# max32665 register map
Vendor: Maxim-Integrated; Series: ARMCM3; File version: 1.0
CPU: CM4 r2p1, little endian, MPU, FPU, 3 interrupt priority bits
Registers are 32-bit, read-write, reset 0x0 unless marked. A register's access mark holds for its fields unless they carry their own. Offsets are from the block's base; [hi:lo] are bit positions; {n}, {i} and the like mark numbered series; 'fields as' and 'values as' point back to an identical list.

## SPIXR — SPIXR peripheral.
Base 0x4003A000
0x00 DATA32 — Register for reading and writing the FIFO.
  [31:0] DATA — Read to pull from RX FIFO, write to put into TX FIFO.
{0x0+2i} DATA16[{i}] (i=0..1) 16-bit (alternate view of DATA32) — Register for reading and writing the FIFO.
  [15:0] DATA — Read to pull from RX FIFO, write to put into TX FIFO.
{0x0+i} DATA8[{i}] (i=0..3) 8-bit (alternate view of DATA32) — Register for reading and writing the FIFO.
  [7:0] DATA — Read to pull from RX FIFO, write to put into TX FIFO.
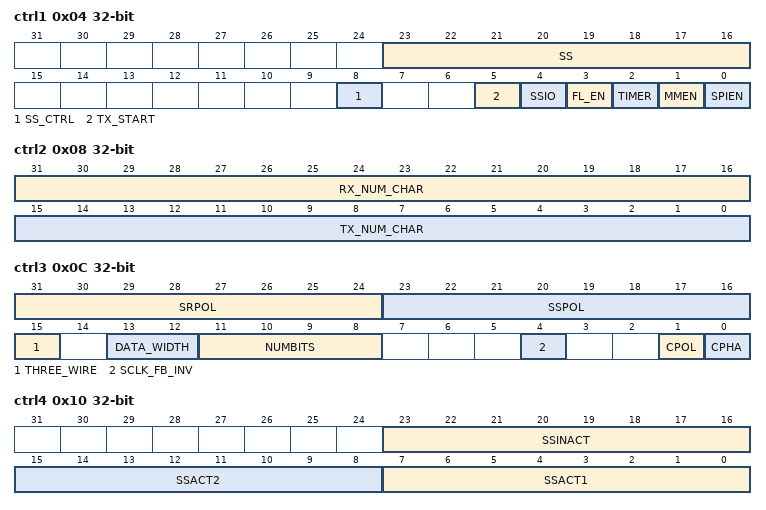
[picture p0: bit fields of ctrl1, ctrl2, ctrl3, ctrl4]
0x04 ctrl1 — Register for controlling SPI peripheral.
  [23:16] SS — Slave Select, when in Master mode selects which Slave devices are selected. More than one Slave device can be selected.
    1=SS0 is selected; 2=SS1 is selected; 4=SS2 is selected; 8=SS3 is selected; 16=SS4 is selected; 32=SS5 is selected; 64=SS6 is selected; 128=SS7 is selected
  [8] SS_CTRL — Slave Select Control.
    0=deassert (SPI de-asserts Slave Select at the end of a transaction.); 1=assert (SPI leaves Slave Select asserted at the end of a transaction.)
  [5] TX_START — Start Transmit.
    1=start (Master Initiates a transaction, this bit is self clearing when transactions are done. If a transaction completes, and the TX FIFO is empty, the Master halts, if a transaction completes, and the TX FIFO is not empty, the Master initiates another transaction.)
  [4] SSIO — Slave Select 0, IO direction, to support Multi-Master mode, Slave Select 0 can be input in Master mode. This bit has no effect in slave mode.
    0=output (Slave select 0 is output.); 1=input (Slave Select 0 is input, only valid if MMEN=1.)
  [3] FL_EN — Flow Control Mode Enable.
    0=dis (Flow Control mode is disabled.); 1=en (Flow Control Mode is enabled.)
  [2] TIMER — Timer Enable.
    0=dis (Timer is disabled.); 1=en (Timer is enabled, only valid if SPIEN=0.)
  [1] MMEN — Master Mode Enable.
    0=dis (SPI is Slave mode.); 1=en (SPI is Master mode.)
  [0] SPIEN — SPI Enable.
    0=dis (SPI is disabled.); 1=en (SPI is enabled.)
0x08 ctrl2 — Register for controlling SPI peripheral.
  [31:16] RX_NUM_CHAR — Nubmer of Characters to receive.
  [15:0] TX_NUM_CHAR — Nubmer of Characters to transmit.
0x0C ctrl3 — Register for controlling SPI peripheral.
  [31:24] SRPOL — Slave Ready Polarity, each Slave Ready can have unique polarity.
    1=SR0_high (SR0 active high.); 2=SR1_high (SR1 active high.); 4=SR2_high (SR2 active high.); 8=SR3_high (SR3 active high.); 16=SR4_high (SR4 active high.); 32=SR5_high (SR5 active high.); 64=SR6_high (SR6 active high.); 128=SR7_high (SR7 active high.)
  [23:16] SSPOL — Slave Select Polarity, each Slave Select can have unique polarity.
    1=SS0_high (SS0 active high.); 2=SS1_high (SS1 active high.); 4=SS2_high (SS2 active high.); 8=SS3_high (SS3 active high.); 16=SS4_high (SS4 active high.); 32=SS5_high (SS5 active high.); 64=SS6_high (SS6 active high.); 128=SS7_high (SS7 active high.)
  [15] THREE_WIRE — Three Wire mode. MOSI/MISO pin(s) shared. Only Mono mode suports Four-Wire.
    0=dis (Use four wire mode (Mono only).); 1=en (Use three wire mode.)
  [13:12] DATA_WIDTH — SPI Data width.
    0=Mono (1 data pin.); 1=Dual (2 data pins.); 2=Quad (4 data pins.)
  [11:8] NUMBITS — Number of Bits per character.
    0=16 bits per character
  [4] SCLK_FB_INV — Invert SCLK Feedback in Master Mode.
    0=NON_INV (SCLK is not inverted to Line Receiver.); 1=INV (SCLK is inverted to Line Receiver.)
  [1] CPOL — Clock Polarity.
  [0] CPHA — Clock Phase.
0x10 ctrl4 — Register for controlling SPI peripheral.
  [23:16] SSINACT — Slave Select Inactive delay.
    0=256 system clocks between transactions
  [15:8] SSACT2 — Slave Select Action delay 2.
    0=256 system clocks between last serial clock edge and SS inactive
  [7:0] SSACT1 — Slave Select Action delay 1.
    0=256 system clocks between SS active and first serial clock edge
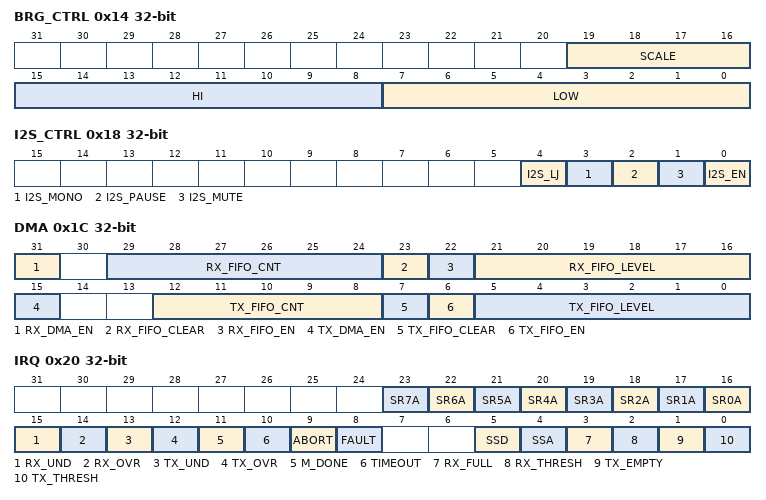
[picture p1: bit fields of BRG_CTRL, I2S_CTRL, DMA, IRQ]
0x14 BRG_CTRL — Register for controlling SPI clock rate.
  [19:16] SCALE — System Clock scale factor. Scales the AMBA clock by 2^SCALE before generating serial clock.
  [15:8] HI — High duty cycle control. In timer mode, reload[15:8].
    0=Dis (Duty cycle control of serial clock generation is disabled.)
  [7:0] LOW — Low duty cycle control. In timer mode, reload[7:0].
    values as HI
0x18 I2S_CTRL — Register for controlling I2C mode.
  [4] I2S_LJ — I2S Left Justify.
    0=dis (Normal I 2 S audio protocol, audio data lags left/right channel signal by one SCLK period.); 1=en (Audio data is synchronized with SSEL (left/right channel signal).)
  [3] I2S_MONO — I2S Monotone.
    0=dis (Stereophonic audio format.); 1=en (Monophonic audio format. Each transmit data word is replicated on both left/right channels. Receive data is taken from left channel, right channel receive data is ignored.)
  [2] I2S_PAUSE
    0=dis (Normal Transmit/Receive.); 1=en (Halt Transmit and Receive FIFO and DMA accesses, Transmit 0s.)
  [1] I2S_MUTE
    0=dis (Normal Transmit.); 1=en (Transmit data is replaced with 0.)
  [0] I2S_EN — Low duty cycle control. In timer mode, reload[7:0].
    0=dis (I2C mode is disabled.); 1=en (I2C mode is enabled.)
0x1C DMA — Register for controlling DMA.
  [31] RX_DMA_EN — RX DMA Enable.
    0=dis (RX DMA requests are disabled, any pending DMA requests are cleared.); 1=en (RX DMA requests are enabled.)
  [29:24] RX_FIFO_CNT — Count of entries in RX FIFO.
  [23] RX_FIFO_CLEAR — Clear RX FIFO, clear is accomplished by resetting the read and write pointers. This should be done when FIFO is not being accessed on the SPI side.
    1=CLEAR (Clear the Receive FIFIO, clears any pending RX FIFO status.)
  [22] RX_FIFO_EN — Receive FIFO enabled for SPI transactions.
    0=DIS (Receive FIFO is not enabled.); 1=en (Receive FIFO is enabled.)
  [21:16] RX_FIFO_LEVEL — Receive FIFO level that will trigger a DMA request, also level for threshold status. When RX FIFO has more than this many bytes, the associated events and conditions are triggered.
  [15] TX_DMA_EN — TX DMA Enable.
    0=DIS (TX DMA requests are disabled, andy pending DMA requests are cleared.); 1=en (TX DMA requests are enabled.)
  [12:8] TX_FIFO_CNT — Count of entries in TX FIFO.
  [7] TX_FIFO_CLEAR — Clear TX FIFO, clear is accomplished by resetting the read and write pointers. This should be done when FIFO is not being accessed on the SPI side.
    1=CLEAR (Clear the Transmit FIFO, clears any pending TX FIFO status.)
  [6] TX_FIFO_EN — Transmit FIFO enabled for SPI transactions.
    0=dis (Transmit FIFO is not enabled.); 1=en (Transmit FIFO is enabled.)
  [5:0] TX_FIFO_LEVEL — Transmit FIFO level that will trigger a DMA request, also level for threshold status. When TX FIFO has fewer than this many bytes, the associated events and conditions are triggered.
0x20 IRQ — Register for reading and clearing interrupt flags. All bits are write 1 to clear.
  [all] fields
    1=clear (Flag is set when value read is 1. Write 1 to clear this flag.)
  [n+16] SR{n}A (n=0..7) — Slave Ready {n} Asserted.
  [15] RX_UND — Receive FIFO Underrun, set when the AMBA side attempts to read data from an empty receive FIFO.
  [14] RX_OVR — Receive FIFO Overrun, set when the SPI side attempts to write to a full receive FIFO.
  [13] TX_UND — Transmit FIFO Underrun, set when the SPI side attempts to read data from an empty transmit FIFO.
  [12] TX_OVR — Transmit FIFO Overrun, set when the AMBA side attempts to write data to a full transmit FIFO.
  [11] M_DONE — Master Done, set when SPI Master has completed any transactions.
  [10] TIMEOUT
  [9] ABORT — Slave Abort Detected.
  [8] FAULT — Multi-Master Mode Fault.
  [5] SSD — Slave Select Deasserted.
  [4] SSA — Slave Select Asserted.
  [3] RX_FULL — RX FIFO FULL.
  [2] RX_THRESH — RX FIFO Threshold Crossed.
  [1] TX_EMPTY — TX FIFO Empty.
  [0] TX_THRESH — TX FIFO Threshold Crossed.
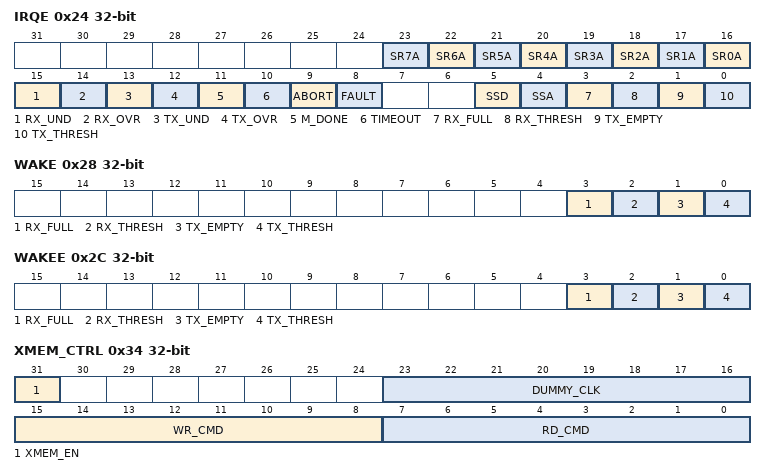
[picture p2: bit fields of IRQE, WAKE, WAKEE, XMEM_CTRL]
0x24 IRQE — Register for enabling interrupts.
  [all] fields
    0=dis (Interrupt is disabled.); 1=en (Interrupt is enabled.)
  [n+16] SR{n}A (n=0..7) — Slave Ready {n} Asserted interrupt enable.
  [15] RX_UND — Receive FIFO Underrun interrupt enable.
  [14] RX_OVR — Receive FIFO Overrun interrupt enable.
  [13] TX_UND — Transmit FIFO Underrun interrupt enable.
  [12] TX_OVR — Transmit FIFO Overrun interrupt enable.
  [11] M_DONE — Master Done interrupt enable.
  [10] TIMEOUT — Timeout interrupt enable.
  [9] ABORT — Slave Abort Detected interrupt enable.
  [8] FAULT — Multi-Master Mode Fault interrupt enable.
  [5] SSD — Slave Select Deasserted interrupt enable.
  [4] SSA — Slave Select Asserted interrupt enable.
  [3] RX_FULL — RX FIFO FULL interrupt enable.
  [2] RX_THRESH — RX FIFO Threshold Crossed interrupt enable.
  [1] TX_EMPTY — TX FIFO Empty interrupt enable.
  [0] TX_THRESH — TX FIFO Threshold interrupt enable.
0x28 WAKE — Register for wake up flags. All bits in this register are write 1 to clear.
  [all] fields
    values as the fields of IRQ
  [3] RX_FULL — Wake on RX FIFO Full.
  [2] RX_THRESH — Wake on RX FIFO Threshold Crossed.
  [1] TX_EMPTY — Wake on TX FIFO Empty.
  [0] TX_THRESH — Wake on TX FIFO Threshold Crossed.
0x2C WAKEE — Register for wake up enable.
  [all] fields
    0=dis (Wakeup source disabled.); 1=en (Wakeup source enabled.)
  [3] RX_FULL — Wake on RX FIFO Full Enable.
  [2] RX_THRESH — Wake on RX FIFO Threshold Crossed Enable.
  [1] TX_EMPTY — Wake on TX FIFO Empty Enable.
  [0] TX_THRESH — Wake on TX FIFO Threshold Crossed Enable.
0x30 STAT ro — SPI Status register.
  [0] BUSY — SPI active status. In Master mode, set when transaction starts, cleared when last bit of last character is acted upon and Slave Select de-assertion would occur. In Slave mode, set when Slave Select is asserted, cleared when Slave Select is de-asserted. Not used in Timer mode.
    0=not (SPI not active.); 1=active (SPI active.)
0x34 XMEM_CTRL — Register to control external memory.
  [31] XMEM_EN — XMEM enable.
  [23:16] DUMMY_CLK — Dummy clocks.
  [15:8] WR_CMD — Write command.
  [7:0] RD_CMD — Read command.
